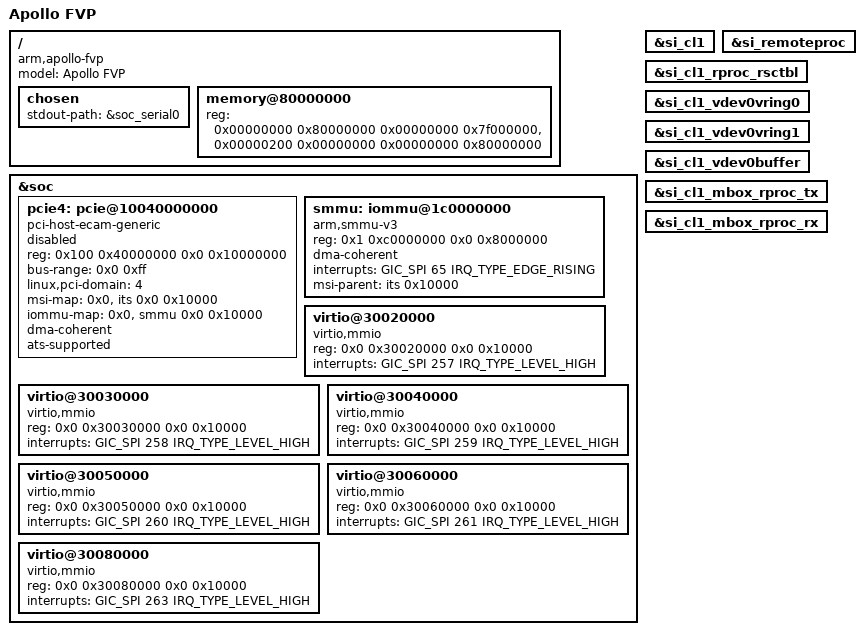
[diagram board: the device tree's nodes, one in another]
// SPDX-License-Identifier: (GPL-2.0 OR BSD-3-Clause)
/*
 * Copyright (c) 2025-2026, Arm Limited. All rights reserved.
 */

/dts-v1/;

#include "apollo-fvp.dtsi"

/ {
	model = "Apollo FVP";
	compatible = "arm,apollo-fvp", "arm,zena-css", "arm,vexpress";

	chosen {
		stdout-path = &soc_serial0;
	};

	memory@80000000 {
		device_type = "memory";

		/* ~2GB mapped at 2GB, another 2GB at 2TB */
		reg = <0x00000000 0x80000000 0x00000000 0x7f000000>,
		<0x00000200 0x00000000 0x00000000 0x80000000>;
	};
};

&soc {
	pcie4: pcie@10040000000 {
		compatible = "pci-host-ecam-generic";
		/* Enable only for PCIe qualification: ECAM reads can raise SError. */
		status = "disabled";
		device_type = "pci";
		#address-cells = <3>;
		#size-cells = <2>;
		reg = <0x100 0x40000000 0x0 0x10000000>;
		bus-range = <0x0 0xff>;
		linux,pci-domain = <4>;
		ranges = <0x02000000 0x0 0x60000000
			  0x0 0x60000000 0x0 0x20000000>,
			 <0x43000000 0x101 0x60000000
			  0x101 0x60000000 0x0 0x20000000>;
		msi-map = <0x0 &its 0x0 0x10000>;
		iommu-map = <0x0 &smmu 0x0 0x10000>;
		dma-coherent;
		ats-supported;
	};

	smmu: iommu@1c0000000 {
		compatible = "arm,smmu-v3";
		reg = <0x1 0xc0000000 0x0 0x8000000>;
		dma-coherent;
		#iommu-cells = <1>;
		interrupts = <GIC_SPI 65 IRQ_TYPE_EDGE_RISING>;
		interrupt-names = "combined";
		msi-parent = <&its 0x10000>;
	};

	virtio@30020000 {
		compatible = "virtio,mmio";
		reg = <0x0 0x30020000 0x0 0x10000>;
		interrupts = <GIC_SPI 257 IRQ_TYPE_LEVEL_HIGH>;
	};

	virtio@30030000 {
		compatible = "virtio,mmio";
		reg = <0x0 0x30030000 0x0 0x10000>;
		interrupts = <GIC_SPI 258 IRQ_TYPE_LEVEL_HIGH>;
	};

	virtio@30040000 {
		compatible = "virtio,mmio";
		reg = <0x0 0x30040000 0x0 0x10000>;
		interrupts = <GIC_SPI 259 IRQ_TYPE_LEVEL_HIGH>;
	};

	virtio@30050000 {
		compatible = "virtio,mmio";
		reg = <0x0 0x30050000 0x0 0x10000>;
		interrupts = <GIC_SPI 260 IRQ_TYPE_LEVEL_HIGH>;
	};

	virtio@30060000 {
		compatible = "virtio,mmio";
		reg = <0x0 0x30060000 0x0 0x10000>;
		interrupts = <GIC_SPI 261 IRQ_TYPE_LEVEL_HIGH>;
	};

	virtio@30080000 {
		compatible = "virtio,mmio";
		reg = <0x0 0x30080000 0x0 0x10000>;
		interrupts = <GIC_SPI 263 IRQ_TYPE_LEVEL_HIGH>;
	};
};

&si_cl1 {
	status = "okay";
};

&si_remoteproc {
	status = "okay";
};

&si_cl1_rproc_rsctbl {
	status = "okay";
};

&si_cl1_vdev0vring0 {
	status = "okay";
};

&si_cl1_vdev0vring1 {
	status = "okay";
};

&si_cl1_vdev0buffer {
	status = "okay";
};

&si_cl1_mbox_rproc_tx {
	status = "okay";
};

&si_cl1_mbox_rproc_rx {
	status = "okay";
};
